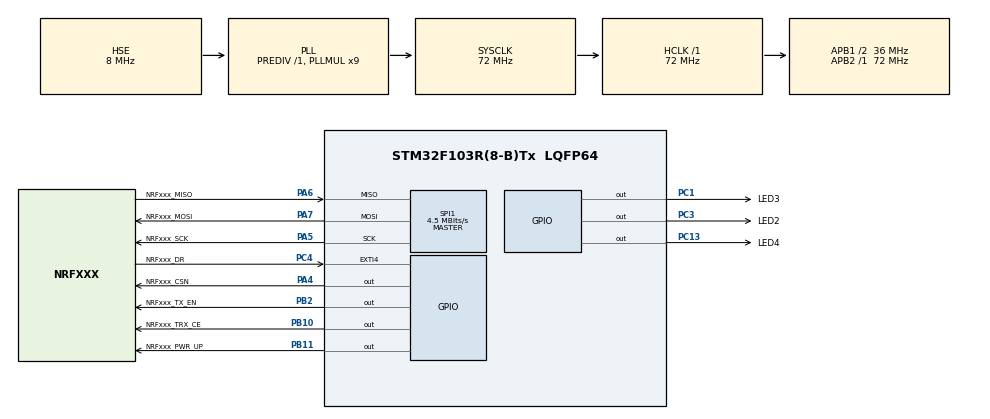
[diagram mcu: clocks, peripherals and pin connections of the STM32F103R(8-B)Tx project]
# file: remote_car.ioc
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Dma.Request0=SPI1_TX
Dma.Request1=SPI1_RX
Dma.SPI1_RX.1.Direction=DMA_PERIPH_TO_MEMORY
Dma.SPI1_RX.1.Instance=DMA1_Channel2
Dma.SPI1_RX.1.MemDataAlignment=DMA_MDATAALIGN_BYTE
Dma.SPI1_RX.1.MemInc=DMA_MINC_ENABLE
Dma.SPI1_RX.1.Mode=DMA_NORMAL
Dma.SPI1_RX.1.PeriphDataAlignment=DMA_PDATAALIGN_BYTE
Dma.SPI1_RX.1.PeriphInc=DMA_PINC_DISABLE
Dma.SPI1_RX.1.Priority=DMA_PRIORITY_LOW
Dma.SPI1_TX.0.Direction=DMA_MEMORY_TO_PERIPH
Dma.SPI1_TX.0.Instance=DMA1_Channel3
Dma.SPI1_TX.0.MemDataAlignment=DMA_MDATAALIGN_BYTE
Dma.SPI1_TX.0.MemInc=DMA_MINC_ENABLE
Dma.SPI1_TX.0.Mode=DMA_NORMAL
Dma.SPI1_TX.0.PeriphDataAlignment=DMA_PDATAALIGN_BYTE
Dma.SPI1_TX.0.PeriphInc=DMA_PINC_DISABLE
Dma.SPI1_TX.0.Priority=DMA_PRIORITY_LOW
FREERTOS.BinarySemaphores01=nRFxxxSPIDMACplt,Dynamic,NULL;DataReadySet,Dynamic,NULL
FREERTOS.Mutexes01=nRFxxxOccupy,Dynamic,NULL
FREERTOS.Tasks01=defaultTask,0,128,StartDefaultTask,Default,NULL,Dynamic,NULL,NULL;nRFxxxHandler,-3,128,startNRFxxxTrans,As external,NULL,Dynamic,NULL,NULL
FREERTOS.Timers01=nCarStatus,queryCarStatus,osTimerPeriodic,As external,NULL,Dynamic,NULL
FREERTOS.configTOTAL_HEAP_SIZE=4096
FREERTOS.configUSE_TIMERS=1
Mcu.Family=STM32F1
Mcu.Name=STM32F103R(8-B)Tx
Mcu.Package=LQFP64
NVIC.DMA1_Channel2_IRQn=true\:9\:0\:true\:false\:true\:true\:false
NVIC.DMA1_Channel3_IRQn=true\:8\:0\:true\:false\:true\:true\:false
NVIC.EXTI4_IRQn=true\:7\:0\:true\:false\:true\:true\:true
NVIC.PriorityGroup=NVIC_PRIORITYGROUP_4
NVIC.TIM1_UP_IRQn=true\:0\:0\:false\:false\:true\:false\:false
NVIC.TimeBase=TIM1_UP_IRQn
NVIC.TimeBaseIP=TIM1
PA13.Mode=Trace_Asynchronous_SW
PA13.Signal=SYS_JTMS-SWDIO
PA14.Mode=Trace_Asynchronous_SW
PA14.Signal=SYS_JTCK-SWCLK
PA4.GPIO_Label=NRFxxx_CSN
PA4.Signal=GPIO_Output
PA5.GPIO_Label=NRFxxx_SCK
PA5.Mode=Full_Duplex_Master
PA5.Signal=SPI1_SCK
PA6.GPIO_Label=NRFxxx_MISO
PA6.Mode=Full_Duplex_Master
PA6.Signal=SPI1_MISO
PA7.GPIO_Label=NRFxxx_MOSI
PA7.Mode=Full_Duplex_Master
PA7.Signal=SPI1_MOSI
PB10.GPIO_Label=NRFxxx_TRX_CE
PB10.Signal=GPIO_Output
PB11.GPIO_Label=NRFxxx_PWR_UP
PB11.Signal=GPIO_Output
PB2.GPIO_Label=NRFxxx_TX_EN
PB2.Signal=GPIO_Output
PB3.Mode=Trace_Asynchronous_SW
PB3.Signal=SYS_JTDO-TRACESWO
PC1.GPIO_Label=LED3
PC1.PinState=GPIO_PIN_SET
PC1.Signal=GPIO_Output
PC13-TAMPER-RTC.GPIO_Label=LED4
PC13-TAMPER-RTC.PinState=GPIO_PIN_SET
PC13-TAMPER-RTC.Signal=GPIO_Output
PC14-OSC32_IN.Mode=LSE-External-Oscillator
PC14-OSC32_IN.Signal=RCC_OSC32_IN
PC15-OSC32_OUT.Mode=LSE-External-Oscillator
PC15-OSC32_OUT.Signal=RCC_OSC32_OUT
PC3.GPIO_Label=LED2
PC3.PinState=GPIO_PIN_SET
PC3.Signal=GPIO_Output
PC4.GPIO_Label=NRFxxx_DR
PC4.Signal=GPXTI4
PD0-OSC_IN.Mode=HSE-External-Oscillator
PD0-OSC_IN.Signal=RCC_OSC_IN
PD1-OSC_OUT.Mode=HSE-External-Oscillator
PD1-OSC_OUT.Signal=RCC_OSC_OUT
ProjectManager.HeapSize=0x200
ProjectManager.StackSize=0x400
ProjectManager.TargetToolchain=MDK-ARM V5
RCC.AHBFreq_Value=72000000
RCC.APB1CLKDivider=RCC_HCLK_DIV2
RCC.APB1Freq_Value=36000000
RCC.APB1TimFreq_Value=72000000
RCC.APB2Freq_Value=72000000
RCC.APB2TimFreq_Value=72000000
RCC.HCLKFreq_Value=72000000
RCC.PLLMUL=RCC_PLL_MUL9
RCC.PLLSourceVirtual=RCC_PLLSOURCE_HSE
RCC.RCC_MCOSource=RCC_MCO1SOURCE_PLLCLK
RCC.RTCClockSelection=RCC_RTCCLKSOURCE_LSE
RCC.SYSCLKFreq_VALUE=72000000
RCC.SYSCLKSource=RCC_SYSCLKSOURCE_PLLCLK
RCC.USBFreq_Value=72000000
SPI1.BaudRatePrescaler=SPI_BAUDRATEPRESCALER_16
SPI1.CalculateBaudRate=4.5 MBits/s
SPI1.Direction=SPI_DIRECTION_2LINES
SPI1.Mode=SPI_MODE_MASTER
SPI1.VirtualType=VM_MASTER
VP_FREERTOS_VS_ENABLE.Mode=Enabled
VP_SYS_VS_tim1.Mode=TIM1
board=remote_car

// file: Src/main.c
/**
  ******************************************************************************
  * File Name          : main.c
  * Description        : Main program body
  ******************************************************************************
  * This notice applies to any and all portions of this file
  * that are not between comment pairs USER CODE BEGIN and
  * USER CODE END. Other portions of this file, whether
  * inserted by the user or by software development tools
  * are owned by their respective copyright owners.
  *
  * Copyright (c) 2017 STMicroelectronics International N.V.
  * All rights reserved.
  *
  * Redistribution and use in source and binary forms, with or without
  * modification, are permitted, provided that the following conditions are met:
  *
  * 1. Redistribution of source code must retain the above copyright notice,
  *    this list of conditions and the following disclaimer.
  * 2. Redistributions in binary form must reproduce the above copyright notice,
  *    this list of conditions and the following disclaimer in the documentation
  *    and/or other materials provided with the distribution.
  * 3. Neither the name of STMicroelectronics nor the names of other
  *    contributors to this software may be used to endorse or promote products
  *    derived from this software without specific written permission.
  * 4. This software, including modifications and/or derivative works of this
  *    software, must execute solely and exclusively on microcontroller or
  *    microprocessor devices manufactured by or for STMicroelectronics.
  * 5. Redistribution and use of this software other than as permitted under
  *    this license is void and will automatically terminate your rights under
  *    this license.
  *
  * THIS SOFTWARE IS PROVIDED BY STMICROELECTRONICS AND CONTRIBUTORS "AS IS"
  * AND ANY EXPRESS, IMPLIED OR STATUTORY WARRANTIES, INCLUDING, BUT NOT
  * LIMITED TO, THE IMPLIED WARRANTIES OF MERCHANTABILITY, FITNESS FOR A
  * PARTICULAR PURPOSE AND NON-INFRINGEMENT OF THIRD PARTY INTELLECTUAL PROPERTY
  * RIGHTS ARE DISCLAIMED TO THE FULLEST EXTENT PERMITTED BY LAW. IN NO EVENT
  * SHALL STMICROELECTRONICS OR CONTRIBUTORS BE LIABLE FOR ANY DIRECT, INDIRECT,
  * INCIDENTAL, SPECIAL, EXEMPLARY, OR CONSEQUENTIAL DAMAGES (INCLUDING, BUT NOT
  * LIMITED TO, PROCUREMENT OF SUBSTITUTE GOODS OR SERVICES; LOSS OF USE, DATA,
  * OR PROFITS; OR BUSINESS INTERRUPTION) HOWEVER CAUSED AND ON ANY THEORY OF
  * LIABILITY, WHETHER IN CONTRACT, STRICT LIABILITY, OR TORT (INCLUDING
  * NEGLIGENCE OR OTHERWISE) ARISING IN ANY WAY OUT OF THE USE OF THIS SOFTWARE,
  * EVEN IF ADVISED OF THE POSSIBILITY OF SUCH DAMAGE.
  *
  ******************************************************************************
  */

#include "main.h"
#include "stm32f1xx_hal.h"
#include "cmsis_os.h"

/* USER CODE BEGIN Includes */
#ifdef NRF905_AS_RF
#define NRFxxx_DR_PIN_ISR_EDGE		GPIO_MODE_IT_RISING
#else
#define NRFxxx_DR_PIN_ISR_EDGE		GPIO_MODE_IT_FALLING
#endif
/* USER CODE END Includes */

SPI_HandleTypeDef hspi1;
DMA_HandleTypeDef hdma_spi1_tx;
DMA_HandleTypeDef hdma_spi1_rx;

osThreadId defaultTaskHandle;
osThreadId nRFxxxHandlerHandle;
osTimerId nCarStatusHandle;
osMutexId nRFxxxOccupyHandle;
osSemaphoreId nRFxxxSPIDMACpltHandle;
osSemaphoreId DataReadySetHandle;

/* USER CODE BEGIN PV */
/* Private variables ---------------------------------------------------------*/

/* USER CODE END PV */

void SystemClock_Config(void);
static void MX_GPIO_Init(void);
static void MX_DMA_Init(void);
static void MX_SPI1_Init(void);
void StartDefaultTask(void const * argument);
extern void startNRFxxxTrans(void const * argument);
extern void queryCarStatus(void const * argument);

/* USER CODE BEGIN PFP */
/* Private function prototypes -----------------------------------------------*/

/* USER CODE END PFP */

int main(void)
{

  /* MCU Configuration----------------------------------------------------------*/

  /* Reset of all peripherals, Initializes the Flash interface and the Systick. */
  HAL_Init();

  /* Configure the system clock */
  SystemClock_Config();

  /* Initialize all configured peripherals */
  MX_GPIO_Init();
  MX_DMA_Init();
  MX_SPI1_Init();

  /* Create the mutex(es) */
  /* definition and creation of nRFxxxOccupy */
  osMutexDef(nRFxxxOccupy);
  nRFxxxOccupyHandle = osMutexCreate(osMutex(nRFxxxOccupy));

  /* Create the semaphores(s) */
  /* definition and creation of nRFxxxSPIDMACplt */
  osSemaphoreDef(nRFxxxSPIDMACplt);
  nRFxxxSPIDMACpltHandle = osSemaphoreCreate(osSemaphore(nRFxxxSPIDMACplt), 1);

  /* definition and creation of DataReadySet */
  osSemaphoreDef(DataReadySet);
  DataReadySetHandle = osSemaphoreCreate(osSemaphore(DataReadySet), 1);

  /* Create the timer(s) */
  /* definition and creation of nCarStatus */
  osTimerDef(nCarStatus, queryCarStatus);
  nCarStatusHandle = osTimerCreate(osTimer(nCarStatus), osTimerPeriodic, NULL);

  /* Create the thread(s) */
  /* definition and creation of defaultTask */
  osThreadDef(defaultTask, StartDefaultTask, osPriorityNormal, 0, 128);
  defaultTaskHandle = osThreadCreate(osThread(defaultTask), NULL);

  /* definition and creation of nRFxxxHandler */
  osThreadDef(nRFxxxHandler, startNRFxxxTrans, osPriorityIdle, 0, 128);
  nRFxxxHandlerHandle = osThreadCreate(osThread(nRFxxxHandler), NULL);

  /* Start scheduler */
  osKernelStart();

  /* We should never get here as control is now taken by the scheduler */

  /* Infinite loop */
  while (1)
  {

  }

}

/** System Clock Configuration
*/
void SystemClock_Config(void)
{

  RCC_OscInitTypeDef RCC_OscInitStruct;
  RCC_ClkInitTypeDef RCC_ClkInitStruct;

    /**Initializes the CPU, AHB and APB busses clocks
    */
  RCC_OscInitStruct.OscillatorType = RCC_OSCILLATORTYPE_HSE;
  RCC_OscInitStruct.HSEState = RCC_HSE_ON;
  RCC_OscInitStruct.HSEPredivValue = RCC_HSE_PREDIV_DIV1;
  RCC_OscInitStruct.HSIState = RCC_HSI_ON;
  RCC_OscInitStruct.PLL.PLLState = RCC_PLL_ON;
  RCC_OscInitStruct.PLL.PLLSource = RCC_PLLSOURCE_HSE;
  RCC_OscInitStruct.PLL.PLLMUL = RCC_PLL_MUL9;
  if (HAL_RCC_OscConfig(&RCC_OscInitStruct) != HAL_OK)
  {
    _Error_Handler(__FILE__, __LINE__);
  }

    /**Initializes the CPU, AHB and APB busses clocks
    */
  RCC_ClkInitStruct.ClockType = RCC_CLOCKTYPE_HCLK|RCC_CLOCKTYPE_SYSCLK
                              |RCC_CLOCKTYPE_PCLK1|RCC_CLOCKTYPE_PCLK2;
  RCC_ClkInitStruct.SYSCLKSource = RCC_SYSCLKSOURCE_PLLCLK;
  RCC_ClkInitStruct.AHBCLKDivider = RCC_SYSCLK_DIV1;
  RCC_ClkInitStruct.APB1CLKDivider = RCC_HCLK_DIV2;
  RCC_ClkInitStruct.APB2CLKDivider = RCC_HCLK_DIV1;

  if (HAL_RCC_ClockConfig(&RCC_ClkInitStruct, FLASH_LATENCY_2) != HAL_OK)
  {
    _Error_Handler(__FILE__, __LINE__);
  }

    /**Configure the Systick interrupt time
    */
  HAL_SYSTICK_Config(HAL_RCC_GetHCLKFreq()/1000);

    /**Configure the Systick
    */
  HAL_SYSTICK_CLKSourceConfig(SYSTICK_CLKSOURCE_HCLK);

  /* SysTick_IRQn interrupt configuration */
  HAL_NVIC_SetPriority(SysTick_IRQn, 15, 0);
}

/* SPI1 init function */
static void MX_SPI1_Init(void)
{

  /* SPI1 parameter configuration*/
  hspi1.Instance = SPI1;
  hspi1.Init.Mode = SPI_MODE_MASTER;
  hspi1.Init.Direction = SPI_DIRECTION_2LINES;
  hspi1.Init.DataSize = SPI_DATASIZE_8BIT;
  hspi1.Init.CLKPolarity = SPI_POLARITY_LOW;
  hspi1.Init.CLKPhase = SPI_PHASE_1EDGE;
  hspi1.Init.NSS = SPI_NSS_SOFT;
  hspi1.Init.BaudRatePrescaler = SPI_BAUDRATEPRESCALER_16;
  hspi1.Init.FirstBit = SPI_FIRSTBIT_MSB;
  hspi1.Init.TIMode = SPI_TIMODE_DISABLE;
  hspi1.Init.CRCCalculation = SPI_CRCCALCULATION_DISABLE;
  hspi1.Init.CRCPolynomial = 10;
  if (HAL_SPI_Init(&hspi1) != HAL_OK)
  {
    _Error_Handler(__FILE__, __LINE__);
  }

}

static void MX_DMA_Init(void)
{
  /* DMA controller clock enable */
  __HAL_RCC_DMA1_CLK_ENABLE();

  /* DMA interrupt init */
  /* DMA1_Channel2_IRQn interrupt configuration */
  HAL_NVIC_SetPriority(DMA1_Channel2_IRQn, 9, 0);
  HAL_NVIC_EnableIRQ(DMA1_Channel2_IRQn);
  /* DMA1_Channel3_IRQn interrupt configuration */
  HAL_NVIC_SetPriority(DMA1_Channel3_IRQn, 8, 0);
  HAL_NVIC_EnableIRQ(DMA1_Channel3_IRQn);

}

/** Configure pins as
        * Analog
        * Input
        * Output
        * EVENT_OUT
        * EXTI
*/
static void MX_GPIO_Init(void)
{

  GPIO_InitTypeDef GPIO_InitStruct;

  /* GPIO Ports Clock Enable */
  __HAL_RCC_GPIOC_CLK_ENABLE();
  __HAL_RCC_GPIOD_CLK_ENABLE();
  __HAL_RCC_GPIOA_CLK_ENABLE();
  __HAL_RCC_GPIOB_CLK_ENABLE();

  /*Configure GPIO pin Output Level */
  HAL_GPIO_WritePin(GPIOC, LED4_Pin|LED3_Pin|LED2_Pin, GPIO_PIN_SET);

  /*Configure GPIO pin Output Level */
  HAL_GPIO_WritePin(NRFxxx_CSN_GPIO_Port, NRFxxx_CSN_Pin, GPIO_PIN_RESET);

  /*Configure GPIO pin Output Level */
  HAL_GPIO_WritePin(GPIOB, NRFxxx_TX_EN_Pin|NRFxxx_TRX_CE_Pin|NRFxxx_PWR_UP_Pin, GPIO_PIN_RESET);

  /*Configure GPIO pins : LED4_Pin LED3_Pin LED2_Pin */
  GPIO_InitStruct.Pin = LED4_Pin|LED3_Pin|LED2_Pin;
  GPIO_InitStruct.Mode = GPIO_MODE_OUTPUT_PP;
  GPIO_InitStruct.Speed = GPIO_SPEED_FREQ_LOW;
  HAL_GPIO_Init(GPIOC, &GPIO_InitStruct);

  /*Configure GPIO pin : NRFxxx_CSN_Pin */
  GPIO_InitStruct.Pin = NRFxxx_CSN_Pin;
  GPIO_InitStruct.Mode = GPIO_MODE_OUTPUT_PP;
  GPIO_InitStruct.Speed = GPIO_SPEED_FREQ_LOW;
  HAL_GPIO_Init(NRFxxx_CSN_GPIO_Port, &GPIO_InitStruct);

  /*Configure GPIO pin : NRFxxx_DR_Pin */
  GPIO_InitStruct.Pin = NRFxxx_DR_Pin;
  GPIO_InitStruct.Mode = NRFxxx_DR_PIN_ISR_EDGE;
  GPIO_InitStruct.Pull = GPIO_NOPULL;
  HAL_GPIO_Init(NRFxxx_DR_GPIO_Port, &GPIO_InitStruct);

  /*Configure GPIO pins : NRFxxx_TX_EN_Pin NRFxxx_TRX_CE_Pin NRFxxx_PWR_UP_Pin */
  GPIO_InitStruct.Pin = NRFxxx_TX_EN_Pin|NRFxxx_TRX_CE_Pin|NRFxxx_PWR_UP_Pin;
  GPIO_InitStruct.Mode = GPIO_MODE_OUTPUT_PP;
  GPIO_InitStruct.Speed = GPIO_SPEED_FREQ_LOW;
  HAL_GPIO_Init(GPIOB, &GPIO_InitStruct);

  /* EXTI interrupt init*/
  HAL_NVIC_SetPriority(EXTI4_IRQn, 7, 0);
  HAL_NVIC_EnableIRQ(EXTI4_IRQn);

}

/* StartDefaultTask function */
void StartDefaultTask(void const * argument)
{

  for(;;)
  {
    osDelay(1);
  }
}

void HAL_TIM_PeriodElapsedCallback(TIM_HandleTypeDef *htim)
{
  if (htim->Instance == TIM1) {
    HAL_IncTick();
  }
}

void _Error_Handler(char * file, int line)
{
  while(1)
  {
  }
}

/************************ (C) COPYRIGHT STMicroelectronics *****END OF FILE****/
